# R7FA2A2AD register map
Vendor: Renesas Electronics Corporation; Series: RA2A2; File version: 1.20.02
CPU: CM23 r1p0, little endian, MPU, no FPU, VTOR, 2 interrupt priority bits, 32 interrupts
Registers are 8-bit, read-write, reset 0x0 unless marked. A register's access mark holds for its fields unless they carry their own. Offsets are from the block's base; [hi:lo] are bit positions.

## IIC0WU — Inter-Integrated Circuit 0 Wake-up Unit
Base 0x40053014
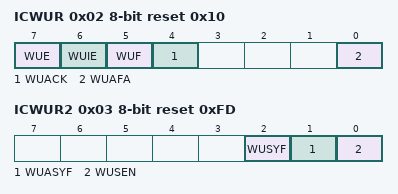
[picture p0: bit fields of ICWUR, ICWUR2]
0x02 ICWUR reset 0x10 — I2C Bus Wakeup Unit Register
  [7] WUE — Wakeup Function Enable
    0=Disable wakeup function; 1=Enable wakeup function
  [6] WUIE — Wakeup Interrupt Request Enable
    0=Disable wakeup interrupt request (IIC0_WUI); 1=Enable wakeup interrupt request (IIC0_WUI)
  [5] WUF — Wakeup Event Occurrence Flag
    0=Slave address not matching during wakeup; 1=Slave address matching during wakeup
  [4] WUACK — ACK Bit for Wakeup Mode
  [0] WUAFA — Wakeup Analog Filter Additional Selection
    0=Do not add the wakeup analog filter; 1=Add the wakeup analog filter
0x03 ICWUR2 reset 0xFD — I2C Bus Wakeup Unit Register 2
  [2] WUSYF ro — Wakeup Function Synchronous Operation Status Flag
    0=IIC asynchronous circuit enable condition; 1=IIC synchronous circuit enable condition
  [1] WUASYF ro — Wakeup Function Asynchronous Operation Status Flag
    0=IIC synchronous circuit enable condition; 1=IIC asynchronous circuit enable condition
  [0] WUSEN — Wakeup Function Synchronous Enable
    0=IIC asynchronous circuit enable; 1=IIC synchronous circuit enable

## DOC — Data Operation Circuit
Base 0x40054100
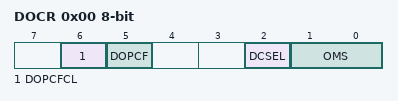
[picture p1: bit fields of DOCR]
0x00 DOCR — DOC Control Register
  [6] DOPCFCL — DOPCF Clear
    0=Retain DOPCF flag state; 1=Clear DOPCF flag
  [5] DOPCF ro — DOC Flag
  [2] DCSEL — Detection Condition Select
    0=Set DOPCF flag when data mismatch is detected; 1=Set DOPCF flag when data match is detected
  [1:0] OMS — Operating Mode Select
    0=Data comparison mode; 1=Data addition mode; 2=Data subtraction mode; 3=Setting prohibited
0x02 DODIR 16-bit — DOC Data Input Register
0x04 DODSR 16-bit — DOC Data Setting Register

## CRC — Cyclic Redundancy Check Calculator
Base 0x40074000
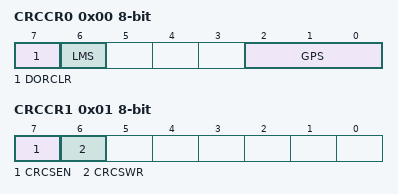
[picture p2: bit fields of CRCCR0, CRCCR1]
0x00 CRCCR0 — CRC Control Register 0
  [7] DORCLR wo — CRCDOR/CRCDOR_HA/CRCDOR_BY Register Clear
    0=No effect; 1=Clear the CRCDOR/CRCDOR_HA/CRCDOR_BY register
  [6] LMS — CRC Calculation Switching
    0=Generate CRC code for LSB-first communication; 1=Generate CRC code for MSB-first communication
  [2:0] GPS — CRC Generating Polynomial Switching
    1=8-bit CRC-8 (X8 + X2 + X + 1); 2=16-bit CRC-16 (X16 + X15 + X2 + 1); 3=16-bit CRC-CCITT (X16 + X12 + X5 + 1); 4=32-bit CRC-32 (X32 + X26 + X23 + X22 + X16 + X12 + X11 +X10 + X8 + X7 + X5 + X4 + X2 + X + 1); 5=32-bit CRC-32C (X32 + X28 + X27 + X26 + X25 + X23 + X22 + X20 + X19 + X18 + X14 + X13 + X11 + X10 + X9 + X8 + X6 + 1); other=Others (No calculation is executed)
0x01 CRCCR1 — CRC Control Register 1
  [7] CRCSEN — Snoop Enable
    0=Disabled; 1=Enabled
  [6] CRCSWR — Snoop-On-Write/Read Switch
    0=Snoop-on-read; 1=Snoop-on-write
0x04 CRCDIR 32-bit — CRC Data Input Register
0x04 CRCDIR_BY (alternate view of CRCDIR) — CRC Data Input Register
0x08 CRCDOR 32-bit — CRC Data Output Register
0x08 CRCDOR_HA 16-bit (alternate view of CRCDOR) — CRC Data Output Register
0x08 CRCDOR_BY (alternate view of CRCDOR) — CRC Data Output Register
0x0C CRCSAR 16-bit — Snoop Address Register
  [13:0] CRCSA — Register Snoop Address

## GPT_OPS — Output Phase Switching Controller
Base 0x40078FF0
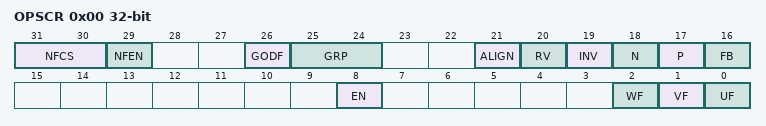
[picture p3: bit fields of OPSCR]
0x00 OPSCR 32-bit — Output Phase Switching Control Register
  [31:30] NFCS — External Input Noise Filter Clock Selection
    0=PCLKD/1; 1=PCLKD/4; 2=PCLKD/16; 3=PCLKD/64
  [29] NFEN — External Input Noise Filter Enable
    0=Do not use a noise filter on the external input; 1=Use a noise filter on the external input
  [26] GODF — Group Output Disable Function
    0=This bit function is ignored; 1=Group disable clears the OPSCR.EN bit
  [25:24] GRP — Output Disabled Source Selection
  [21] ALIGN — Input Phase Alignment
    0=Input phase aligned to PCLKD; 1=Input phase aligned to the falling edge of PWM
  [20] RV — Output Phase Rotation Direction Reversal Control
    0=Positive rotation; 1=Reverse rotation
  [19] INV — Output Phase Invert Control
    0=Positive logic (active-high) output; 1=Negative logic (active-low) output
  [18] N — Negative-Phase Output (N) Control
    0=Level signal output; 1=PWM signal output
  [17] P — Positive-Phase Output (P) Control
    0=Level signal output; 1=PWM signal output
  [16] FB — External Feedback Signal Enable
    0=Do not use; 1=Select the soft setting (OPSCR.UF, VF, WF)
  [8] EN — Output Phase Enable
    0=Do not output (Hi-Z external pin); 1=Output
  [2] WF
  [1] VF
  [0] UF
